# nrf9230_engb_cellrf register map
Vendor: Nordic Semiconductor; Series: nRF92; File version: 1
CPU: CM0 r0p0, little endian, no MPU, no FPU, 2 interrupt priority bits, 33 interrupts
Registers are 32-bit, read-write, reset 0x0 unless marked. A register's access mark holds for its fields unless they carry their own. Offsets are from the block's base; [hi:lo] are bit positions; {n}, {i} and the like mark numbered series; 'fields as' and 'values as' point back to an identical list.

## RFSERVICES — AhmaRfSubsystem general control register map AhmaRfSubsystem general control register map
Base 0x46045000
0x100 EVENTS_LTETIMERSYNC — Rising edge in synchronized LteTimerSync signal
  [0] EVENTS_LTETIMERSYNC
    0=NotGenerated (Event not generated); 1=Generated (Event generated)
0x104 EVENTS_GNSSTIMERSYNC — Rising edge in synchronized gnssTimerSync signal
  [0] EVENTS_GNSSTIMERSYNC
    values as EVENTS_LTETIMERSYNC.EVENTS_LTETIMERSYNC
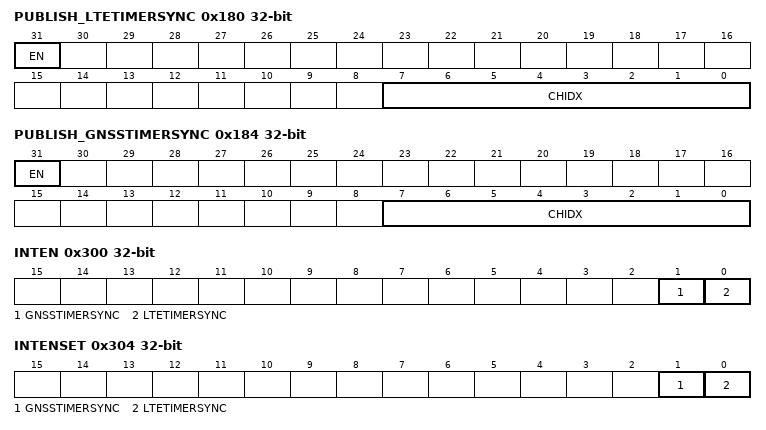
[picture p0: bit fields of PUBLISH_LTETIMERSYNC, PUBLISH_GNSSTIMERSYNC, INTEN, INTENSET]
0x180 PUBLISH_LTETIMERSYNC — Publish configuration for event LTETIMERSYNC
  [31] EN
    0=Disabled (Disable publishing); 1=Enabled (Enable publishing)
  [7:0] CHIDX — DPPI channel that event LTETIMERSYNC will publish to
0x184 PUBLISH_GNSSTIMERSYNC — Publish configuration for event GNSSTIMERSYNC
  [31] EN
    values as PUBLISH_LTETIMERSYNC.EN
  [7:0] CHIDX — DPPI channel that event GNSSTIMERSYNC will publish to
0x300 INTEN — Enable or disable interrupt
  [1] GNSSTIMERSYNC — Enable or disable interrupt for event GNSSTIMERSYNC
    0=Disabled; 1=Enabled
  [0] LTETIMERSYNC — Enable or disable interrupt for event LTETIMERSYNC
    0=Disabled; 1=Enabled
0x304 INTENSET — Enable interrupt
  [1] GNSSTIMERSYNC — Write '1' to enable interrupt for event GNSSTIMERSYNC
    on read: 0=Disabled (Read: Disabled); 1=Enabled (Read: Enabled) | on write: 1=Set (Enable)
  [0] LTETIMERSYNC — Write '1' to enable interrupt for event LTETIMERSYNC
    values as GNSSTIMERSYNC
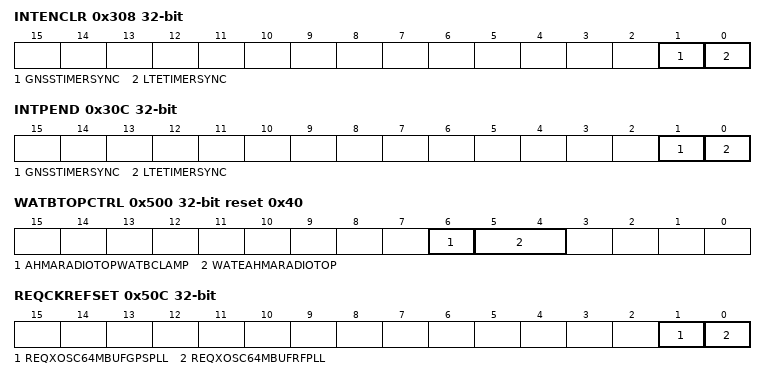
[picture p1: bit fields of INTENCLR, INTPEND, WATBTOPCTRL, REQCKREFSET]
0x308 INTENCLR — Disable interrupt
  [1] GNSSTIMERSYNC — Write '1' to disable interrupt for event GNSSTIMERSYNC
    on read: 0=Disabled (Read: Disabled); 1=Enabled (Read: Enabled) | on write: 1=Clear (Disable)
  [0] LTETIMERSYNC — Write '1' to disable interrupt for event LTETIMERSYNC
    values as GNSSTIMERSYNC
0x30C INTPEND ro — Pending interrupts
  [1] GNSSTIMERSYNC — Read pending status of interrupt for event GNSSTIMERSYNC
    on read: 0=NotPending (Read: Not pending); 1=Pending (Read: Pending)
  [0] LTETIMERSYNC — Read pending status of interrupt for event LTETIMERSYNC
    values as GNSSTIMERSYNC
0x400 CKREQSTATUS ro — Clock request status
  [23:0] CKREQSTATUS — Clock request status for each peripheral
0x500 WATBTOPCTRL reset 0x40 — AHMA_ANA Top level test network control (effective only when dftEnable set high)
  [6] AHMARADIOTOPWATBCLAMP — Test network clamp control. Must be inactivated when top level test switches are on.
    0=Inactive (Clamp inactive); 1=Active (AHMA_ANA internal test network clamped to ground)
  [5:4] WATEAHMARADIOTOP — Top Level test switch enable
    0=Both_Off (Both WATB0 and WATB1 test switches in off state); 1=WATB0_On (AHMA_ANA WATB0 connected to corresponding GPIO analog slice); 2=WATB1_On (AHMA_ANA WATB1 connected to corresponding GPIO analog slice); 3=Both_On (Both WATB0 and WATB1 connected to corresponding GPIO analog slices)
0x504 CKREQTIMEMARK — Clock request control for a registers that captures Lte Timer and Gnss Timer timemark inputs
  [0] CKREQTIMEMARK — Clock Request
    0=Off (Clock request off); 1=On (Clock request on)
0x508 POWERCLOCKMODE — Request Clock and/or Power for RF peripheral domain
  [1:0] POWERCLOCKMODE — Peripheral domain power and clock mode
    0=Power_Off (Peripheral domain is allowed to power off); 1=Clocks_Off (Peripheral domain is not allowed to power off, but is allowed to turn its clocks off); 2=Clocks_Gated (Peripheral domain is not allowed to power off, and its clock generators are kept running while the clocks themselves may be gated); 3=All_On (Peripheral domain is forced to have its clocks running)
0x50C REQCKREFSET write-1-sets — Enable HFXO64M reference clock buffers
  [1] REQXOSC64MBUFGPSPLL — Request 64M reference clock for GPS SX.
    0=NoEffect (Writing 0 has no effect); 1=Set (Writing 1 sets/clears the register)
  [0] REQXOSC64MBUFRFPLL — Request 64M reference clock for RFPLL
    values as REQXOSC64MBUFGPSPLL
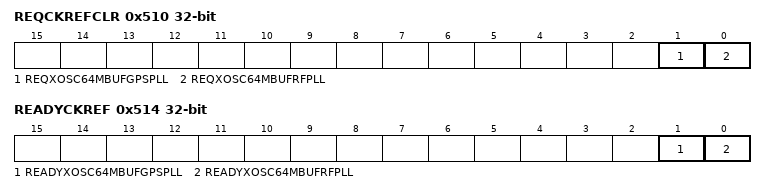
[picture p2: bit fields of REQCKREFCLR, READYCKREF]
0x510 REQCKREFCLR write-1-clears — Enable HFXO64M reference clock buffers
  fields as REQCKREFSET
0x514 READYCKREF ro — Status of HFXO64M reference clock
  [1] READYXOSC64MBUFGPSPLL — Ready indicator for GPS SX reference clock from HFXO64M (synchronized to MCPLL domain)
    0=NotReady (Clock source not ready); 1=Ready (Clock source ready)
  [0] READYXOSC64MBUFRFPLL — Ready indicator for RFPLL reference clock from HFXO64M (synchronized to MCPLL domain)
    values as READYXOSC64MBUFGPSPLL
{0x518+4i} RFGPIODEBUG[{i}] (i=0..7) — Description collection: RFGPIO[n] debug source control (effective only when dftEnable set high)
  [2:0] GPIODBGSEL — Selects the source for debug signals and enables the connection to RFGPIO[n]. The source needs to be separately enabled from corresponding peripheral registers (AHMA_RX, AHMA TX and AHMA_RFSERVICES.SX_DEBUGSEL in case of SX debug signals)
    0=Off (No debug signals connected to RFGPIO0 (normal functionality)); 1=SX (AHMA SX (RfPll) debug signals connected to RFGPIO[N]); 2=TX (AHMA TX debug signals connected to RFGPIO[N]); 3=LTERX (AHMA LTE RX debug signals connected to RFGPIO[N]); 4=GNSSRX (AHMA GNSS RX debug signals connected to RFGPIO[N])
{0x538+4i} SXDEBUG[{i}] (i=0..7) — Description collection: SX debug signal selection. Debug1[n]: SX_DEBUGDATA[n] Debug2[0]: SX_DEBUGDATA[8] Debug2[1]: SX_DEBUGDATA[9] Debug2[2]: SX_DEBUGDATA[10] Debug2[3]: SX_DEBUGDATA[11] Debug2[4]: Debug2[5]: Debug2[6]: SX_DEBUGBUSSTROBE Debug2[7]: SX_FCOMPMEAS_OUT
  [1:0] SXDBGSEL — Select SX debug signal connected to RFGPIO[N]
    0=NoConnection (Nothing connected to debug output); 1=Debug1 (Debug signal selection 1); 2=Debug2 (Debug signal selection 2); 3=NotUsed
0x558 VBATSCALERCTRL — Controls for VBAT Scaler IO
  [0] VBATSCALERENABLE — Enables the VBAT voltage scaler for measuring battery voltage. Scaler itself is located outside of CellRF (padring).
    0=Off (VBAT Scaler enabled); 1=On (VBAT Scaler disabled)
0x55C PADCONFPOWERREQ — Request Power for the domain storing PAD configurations.
  [0] EN — Enables power request for PD_GD_CORE3_ACT domain. When set, it will be ensured that the PAD configurations in GPIO peripheral will not be reset before PAD retention is applied.
    0=Off (Power request disabled); 1=On (Power request enabled)
